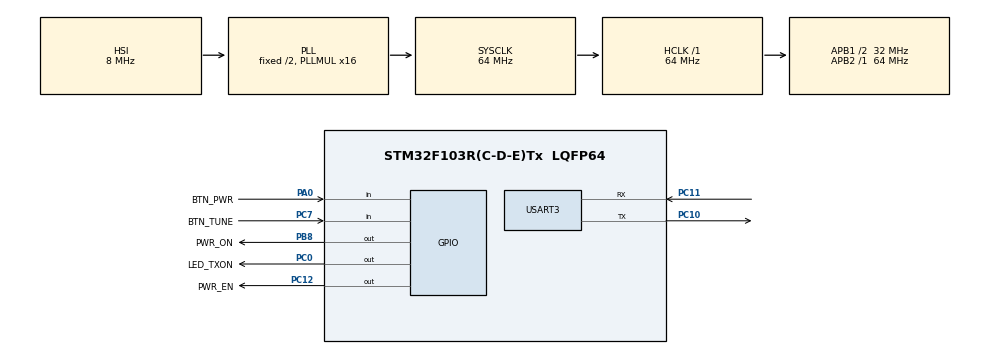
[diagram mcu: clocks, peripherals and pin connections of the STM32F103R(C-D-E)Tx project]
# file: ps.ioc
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Mcu.Family=STM32F1
Mcu.Name=STM32F103R(C-D-E)Tx
Mcu.Package=LQFP64
NVIC.PriorityGroup=NVIC_PRIORITYGROUP_4
PA0-WKUP.GPIO_Label=BTN_PWR
PA0-WKUP.GPIO_PuPd=GPIO_PULLUP
PA0-WKUP.Signal=GPIO_Input
PB8.GPIO_Label=PWR_ON
PB8.Signal=GPIO_Output
PC0.GPIO_Label=LED_TXON
PC0.Signal=GPIO_Output
PC10.Mode=Asynchronous
PC10.Signal=USART3_TX
PC11.Mode=Asynchronous
PC11.Signal=USART3_RX
PC12.GPIO_Label=PWR_EN
PC12.Signal=GPIO_Output
PC7.GPIO_Label=BTN_TUNE
PC7.GPIO_PuPd=GPIO_PULLUP
PC7.Signal=GPIO_Input
ProjectManager.HeapSize=0x200
ProjectManager.StackSize=0x400
ProjectManager.TargetToolchain=STM32CubeIDE
RCC.AHBFreq_Value=64000000
RCC.APB1CLKDivider=RCC_HCLK_DIV2
RCC.APB1Freq_Value=32000000
RCC.APB1TimFreq_Value=64000000
RCC.APB2Freq_Value=64000000
RCC.APB2TimFreq_Value=64000000
RCC.HCLKFreq_Value=64000000
RCC.PLLMUL=RCC_PLL_MUL16
RCC.SYSCLKFreq_VALUE=64000000
RCC.SYSCLKSource=RCC_SYSCLKSOURCE_PLLCLK
RCC.USBFreq_Value=64000000
USART3.VirtualMode=VM_ASYNC
VP_SYS_VS_ND.Mode=No_Debug
board=custom

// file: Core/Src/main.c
/* USER CODE BEGIN Header */
/**
  ******************************************************************************
  * @file           : main.c
  * @brief          : Main program body
  ******************************************************************************
  * @attention
  *
  * Copyright (c) 2025 STMicroelectronics.
  * All rights reserved.
  *
  * This software is licensed under terms that can be found in the LICENSE file
  * in the root directory of this software component.
  * If no LICENSE file comes with this software, it is provided AS-IS.
  *
  ******************************************************************************
  */
/* USER CODE END Header */
#include "main.h"

/* USER CODE BEGIN Includes */
#include "gpio.h"
#include "cmd.h"
/* USER CODE END Includes */

UART_HandleTypeDef huart3;

void SystemClock_Config(void);
static void MX_GPIO_Init(void);
static void MX_USART3_UART_Init(void);

int main(void)
{

  /* MCU Configuration--------------------------------------------------------*/

  /* Reset of all peripherals, Initializes the Flash interface and the Systick. */
  HAL_Init();

  /* Configure the system clock */
  SystemClock_Config();

  /* Initialize all configured peripherals */
  MX_GPIO_Init();
  MX_USART3_UART_Init();

  /* Infinite loop */
  while (1)
  {

    /* USER CODE BEGIN 3 */
	  gpio_tick();
	  cmd_tick();
  }
  /* USER CODE END 3 */
}

void SystemClock_Config(void)
{
  RCC_OscInitTypeDef RCC_OscInitStruct = {0};
  RCC_ClkInitTypeDef RCC_ClkInitStruct = {0};

  /** Initializes the RCC Oscillators according to the specified parameters
  * in the RCC_OscInitTypeDef structure.
  */
  RCC_OscInitStruct.OscillatorType = RCC_OSCILLATORTYPE_HSI;
  RCC_OscInitStruct.HSIState = RCC_HSI_ON;
  RCC_OscInitStruct.HSICalibrationValue = RCC_HSICALIBRATION_DEFAULT;
  RCC_OscInitStruct.PLL.PLLState = RCC_PLL_ON;
  RCC_OscInitStruct.PLL.PLLSource = RCC_PLLSOURCE_HSI_DIV2;
  RCC_OscInitStruct.PLL.PLLMUL = RCC_PLL_MUL16;
  if (HAL_RCC_OscConfig(&RCC_OscInitStruct) != HAL_OK)
  {
    Error_Handler();
  }

  /** Initializes the CPU, AHB and APB buses clocks
  */
  RCC_ClkInitStruct.ClockType = RCC_CLOCKTYPE_HCLK|RCC_CLOCKTYPE_SYSCLK
                              |RCC_CLOCKTYPE_PCLK1|RCC_CLOCKTYPE_PCLK2;
  RCC_ClkInitStruct.SYSCLKSource = RCC_SYSCLKSOURCE_PLLCLK;
  RCC_ClkInitStruct.AHBCLKDivider = RCC_SYSCLK_DIV1;
  RCC_ClkInitStruct.APB1CLKDivider = RCC_HCLK_DIV2;
  RCC_ClkInitStruct.APB2CLKDivider = RCC_HCLK_DIV1;

  if (HAL_RCC_ClockConfig(&RCC_ClkInitStruct, FLASH_LATENCY_2) != HAL_OK)
  {
    Error_Handler();
  }
}

static void MX_USART3_UART_Init(void)
{

  huart3.Instance = USART3;
  huart3.Init.BaudRate = 115200;
  huart3.Init.WordLength = UART_WORDLENGTH_8B;
  huart3.Init.StopBits = UART_STOPBITS_1;
  huart3.Init.Parity = UART_PARITY_NONE;
  huart3.Init.Mode = UART_MODE_TX_RX;
  huart3.Init.HwFlowCtl = UART_HWCONTROL_NONE;
  huart3.Init.OverSampling = UART_OVERSAMPLING_16;
  if (HAL_UART_Init(&huart3) != HAL_OK)
  {
    Error_Handler();
  }

}

static void MX_GPIO_Init(void)
{
  GPIO_InitTypeDef GPIO_InitStruct = {0};

  /* GPIO Ports Clock Enable */
  __HAL_RCC_GPIOC_CLK_ENABLE();
  __HAL_RCC_GPIOA_CLK_ENABLE();
  __HAL_RCC_GPIOB_CLK_ENABLE();

  /*Configure GPIO pin Output Level */
  HAL_GPIO_WritePin(GPIOC, LED_TXON_Pin|PWR_EN_Pin, GPIO_PIN_RESET);

  /*Configure GPIO pin Output Level */
  HAL_GPIO_WritePin(PWR_ON_GPIO_Port, PWR_ON_Pin, GPIO_PIN_RESET);

  /*Configure GPIO pins : LED_TXON_Pin PWR_EN_Pin */
  GPIO_InitStruct.Pin = LED_TXON_Pin|PWR_EN_Pin;
  GPIO_InitStruct.Mode = GPIO_MODE_OUTPUT_PP;
  GPIO_InitStruct.Pull = GPIO_NOPULL;
  GPIO_InitStruct.Speed = GPIO_SPEED_FREQ_LOW;
  HAL_GPIO_Init(GPIOC, &GPIO_InitStruct);

  /*Configure GPIO pin : BTN_PWR_Pin */
  GPIO_InitStruct.Pin = BTN_PWR_Pin;
  GPIO_InitStruct.Mode = GPIO_MODE_INPUT;
  GPIO_InitStruct.Pull = GPIO_PULLUP;
  HAL_GPIO_Init(BTN_PWR_GPIO_Port, &GPIO_InitStruct);

  /*Configure GPIO pin : BTN_TUNE_Pin */
  GPIO_InitStruct.Pin = BTN_TUNE_Pin;
  GPIO_InitStruct.Mode = GPIO_MODE_INPUT;
  GPIO_InitStruct.Pull = GPIO_PULLUP;
  HAL_GPIO_Init(BTN_TUNE_GPIO_Port, &GPIO_InitStruct);

  /*Configure GPIO pin : PWR_ON_Pin */
  GPIO_InitStruct.Pin = PWR_ON_Pin;
  GPIO_InitStruct.Mode = GPIO_MODE_OUTPUT_PP;
  GPIO_InitStruct.Pull = GPIO_NOPULL;
  GPIO_InitStruct.Speed = GPIO_SPEED_FREQ_LOW;
  HAL_GPIO_Init(PWR_ON_GPIO_Port, &GPIO_InitStruct);

}

void Error_Handler(void)
{
  __disable_irq();
  while (1)
  {
  }
}
